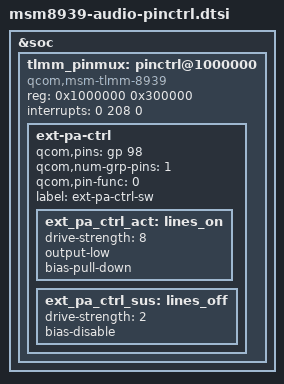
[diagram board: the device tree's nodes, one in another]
/* Copyright (c) 2013-2014, The Linux Foundation. All rights reserved.
 *
 * This program is free software; you can redistribute it and/or modify
 * it under the terms of the GNU General Public License version 2 and
 * only version 2 as published by the Free Software Foundation.
 *
 * This program is distributed in the hope that it will be useful,
 * but WITHOUT ANY WARRANTY; without even the implied warranty of
 * MERCHANTABILITY or FITNESS FOR A PARTICULAR PURPOSE.  See the
 * GNU General Public License for more details.
 */

&soc {
	tlmm_pinmux: pinctrl@1000000 {
		compatible = "qcom,msm-tlmm-8939", "qcom,msm-tlmm-8916";
		reg = <0x1000000 0x300000>;
		interrupts = <0 208 0>;
		
		ext-pa-ctrl {
			qcom,pins = <&gp 98>;
			qcom,num-grp-pins = <1>;
			qcom,pin-func = <0>;
			label = "ext-pa-ctrl-sw";
			ext_pa_ctrl_act: lines_on {
				drive-strength = <8>;
				output-low;
				bias-pull-down;
			};
			ext_pa_ctrl_sus: lines_off {
				drive-strength = <2>;
				bias-disable;
			};
		};

	};
};

